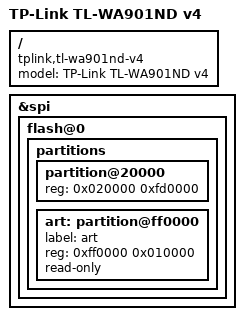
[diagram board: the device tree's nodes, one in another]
// SPDX-License-Identifier: GPL-2.0-or-later OR MIT

#include "tp9343_tplink_tl-wa901nd.dtsi"

/ {
	compatible = "tplink,tl-wa901nd-v4", "qca,tp9343";
	model = "TP-Link TL-WA901ND v4";
};

&spi {
	flash@0 {
		partitions {
			partition@20000 {
				reg = <0x020000 0xfd0000>;
			};

			/delete-node/ partition@3f0000;

			art: partition@ff0000 {
				label = "art";
				reg = <0xff0000 0x010000>;
				read-only;
			};
		};
	};
};
